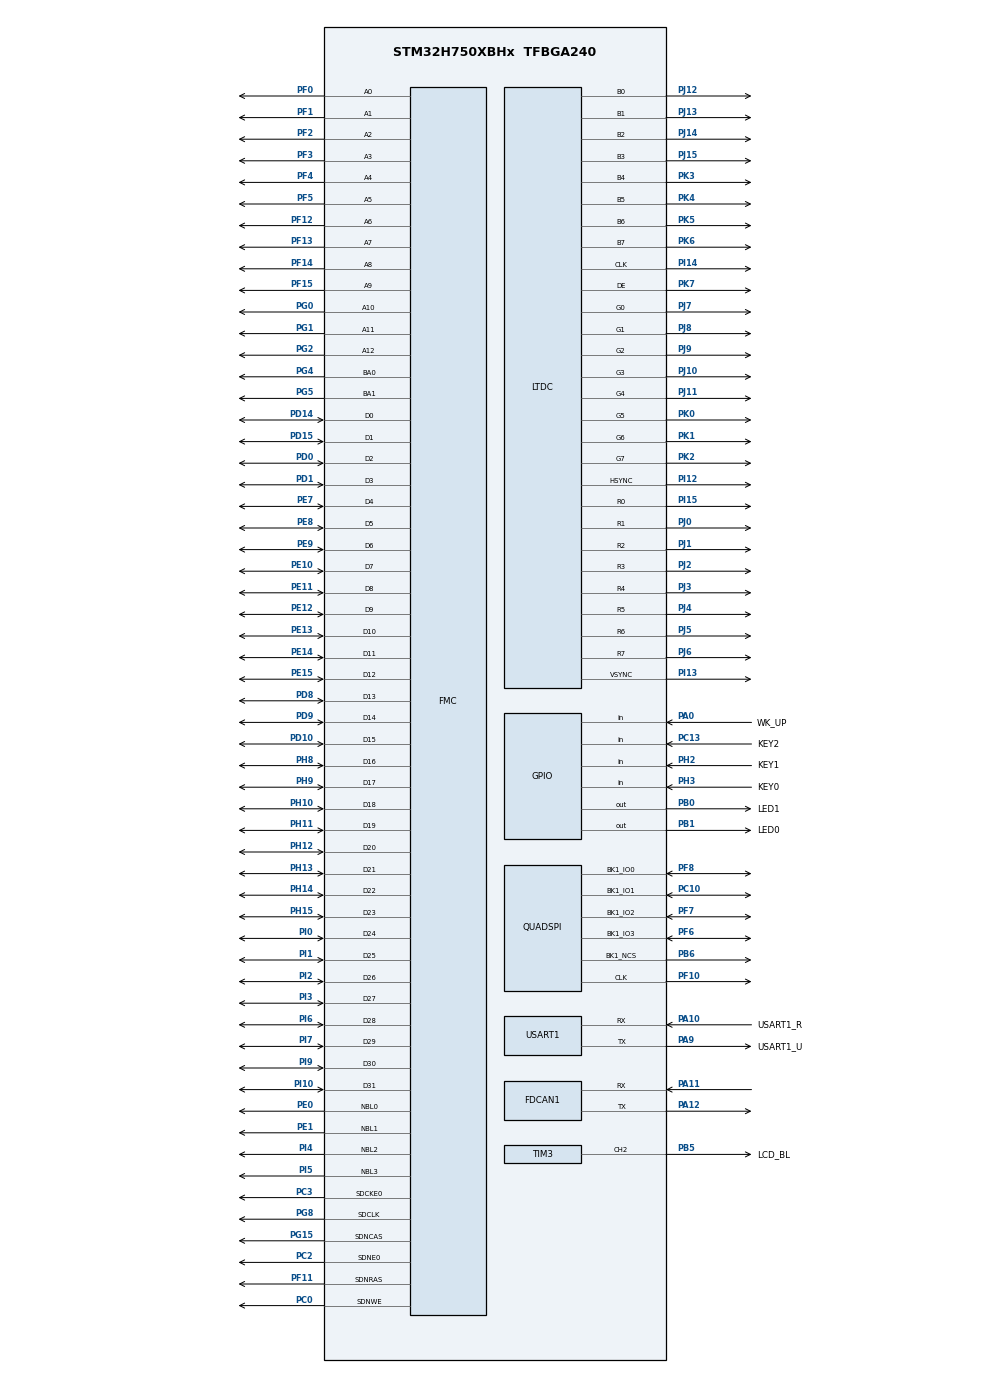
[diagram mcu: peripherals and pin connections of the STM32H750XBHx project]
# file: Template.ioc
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CORTEX_M7.CPU_DCache=Enabled
CORTEX_M7.CPU_ICache=Enabled
CORTEX_M7.default_mode_Activation=1
DMA2D.ColorMode=DMA2D_OUTPUT_RGB565
DMA2D.Mode=DMA2D_M2M
Dma.Request0=USART1_RX
Dma.USART1_RX.0.Direction=DMA_PERIPH_TO_MEMORY
Dma.USART1_RX.0.EventEnable=DISABLE
Dma.USART1_RX.0.FIFOMode=DMA_FIFOMODE_DISABLE
Dma.USART1_RX.0.Instance=DMA1_Stream0
Dma.USART1_RX.0.MemDataAlignment=DMA_MDATAALIGN_BYTE
Dma.USART1_RX.0.MemInc=DMA_MINC_ENABLE
Dma.USART1_RX.0.Mode=DMA_NORMAL
Dma.USART1_RX.0.PeriphDataAlignment=DMA_PDATAALIGN_BYTE
Dma.USART1_RX.0.PeriphInc=DMA_PINC_DISABLE
Dma.USART1_RX.0.Polarity=HAL_DMAMUX_REQ_GEN_RISING
Dma.USART1_RX.0.Priority=DMA_PRIORITY_LOW
Dma.USART1_RX.0.RequestNumber=1
Dma.USART1_RX.0.SignalID=NONE
Dma.USART1_RX.0.SyncEnable=DISABLE
Dma.USART1_RX.0.SyncPolarity=HAL_DMAMUX_SYNC_NO_EVENT
Dma.USART1_RX.0.SyncRequestNumber=1
Dma.USART1_RX.0.SyncSignalID=NONE
FDCAN1.AutoRetransmission=ENABLE
FDCAN1.CalculateBaudRateNominal=500000
FDCAN1.CalculateTimeBitNominal=2000
FDCAN1.CalculateTimeQuantumNominal=40.0
FDCAN1.DataPrescaler=1
FDCAN1.DataSyncJumpWidth=16
FDCAN1.DataTimeSeg1=31
FDCAN1.DataTimeSeg2=3
FDCAN1.ExtFiltersNbr=16
FDCAN1.NominalPrescaler=1
FDCAN1.NominalTimeSeg1=31
FDCAN1.NominalTimeSeg2=18
FDCAN1.RxBuffersNbr=8
FDCAN1.RxFifo0ElmtsNbr=32
FDCAN1.RxFifo1ElmtsNbr=32
FDCAN1.StdFiltersNbr=62
FDCAN1.TxFifoQueueElmtsNbr=32
FMC.CASLatency1=FMC_SDRAM_CAS_LATENCY_2
FMC.ColumnBitsNumber1=FMC_SDRAM_COLUMN_BITS_NUM_9
FMC.ExitSelfRefreshDelay1=8
FMC.LoadToActiveDelay1=2
FMC.RCDDelay1=2
FMC.RPDelay1=2
FMC.ReadBurst1=FMC_SDRAM_RBURST_ENABLE
FMC.ReadPipeDelay1=FMC_SDRAM_RPIPE_DELAY_0
FMC.RowCycleDelay1=7
FMC.SDClockPeriod1=FMC_SDRAM_CLOCK_PERIOD_2
FMC.SelfRefreshTime1=7
FMC.WriteRecoveryTime1=5
FREERTOS.HEAP_NUMBER=4
FREERTOS.Tasks01=GUITask,24,1024,GUI_Task,As weak,NULL,Dynamic,NULL,NULL
FREERTOS.configCHECK_FOR_STACK_OVERFLOW=2
FREERTOS.configENABLE_FPU=1
FREERTOS.configGENERATE_RUN_TIME_STATS=1
FREERTOS.configTIMER_TASK_STACK_DEPTH=512
FREERTOS.configTOTAL_HEAP_SIZE=0x20000
FREERTOS.configUSE_MALLOC_FAILED_HOOK=1
FREERTOS.configUSE_STATS_FORMATTING_FUNCTIONS=1
LTDC.ActiveW=800
LTDC.Alpha_L0=255
LTDC.Alpha_L1=255
LTDC.Blue_L0=0
LTDC.FBStartAdress_L0=0xC0000000
LTDC.HBP=88
LTDC.HFP=40
LTDC.HSync=48
LTDC.ImageHeight_L0=480
LTDC.ImageWidth_L0=800
LTDC.Layers=0
LTDC.PixelFormat_L0=LTDC_PIXEL_FORMAT_RGB565
LTDC.VBP=32
LTDC.VSync=3
LTDC.WindowX0_L1=200
LTDC.WindowX1_L0=800
LTDC.WindowX1_L1=600
LTDC.WindowY0_L1=200
LTDC.WindowY1_L0=480
LTDC.WindowY1_L1=600
Mcu.Family=STM32H7
Mcu.Name=STM32H750XBHx
Mcu.Package=TFBGA240
NVIC.DMA1_Stream0_IRQn=true\:5\:0\:true\:false\:true\:true\:false\:true\:true
NVIC.DMA2D_IRQn=true\:5\:0\:true\:false\:true\:true\:true\:true\:true
NVIC.FDCAN1_IT0_IRQn=true\:5\:0\:true\:false\:true\:true\:true\:true\:true
NVIC.FDCAN1_IT1_IRQn=true\:5\:0\:true\:false\:true\:true\:true\:true\:true
NVIC.FDCAN_CAL_IRQn=true\:5\:0\:true\:false\:true\:true\:true\:true\:true
NVIC.PriorityGroup=NVIC_PRIORITYGROUP_4
NVIC.TIM6_DAC_IRQn=true\:15\:0\:false\:false\:true\:false\:false\:true\:true
NVIC.TimeBase=TIM6_DAC_IRQn
NVIC.TimeBaseIP=TIM6
NVIC.USART1_IRQn=true\:5\:0\:true\:false\:true\:true\:true\:true\:true
PA0.GPIO_Label=WK_UP
PA0.GPIO_PuPd=GPIO_PULLDOWN
PA0.Signal=GPIO_Input
PA10.GPIO_Label=USART1_R
PA10.GPIO_PuPd=GPIO_PULLUP
PA10.Mode=Asynchronous
PA10.Signal=USART1_RX
PA11.GPIO_PuPd=GPIO_PULLUP
PA11.GPIO_Speed=GPIO_SPEED_FREQ_VERY_HIGH
PA11.Mode=FDCAN_Activate
PA11.Signal=FDCAN1_RX
PA12.GPIO_PuPd=GPIO_PULLUP
PA12.GPIO_Speed=GPIO_SPEED_FREQ_VERY_HIGH
PA12.Mode=FDCAN_Activate
PA12.Signal=FDCAN1_TX
PA13\ (JTMS/SWDIO).Mode=Serial_Wire
PA13\ (JTMS/SWDIO).Signal=DEBUG_JTMS-SWDIO
PA14\ (JTCK/SWCLK).Mode=Serial_Wire
PA14\ (JTCK/SWCLK).Signal=DEBUG_JTCK-SWCLK
PA9.GPIO_Label=USART1_U
PA9.Mode=Asynchronous
PA9.Signal=USART1_TX
PB0.GPIO_Label=LED1
PB0.GPIO_PuPd=GPIO_PULLUP
PB0.PinState=GPIO_PIN_SET
PB0.Signal=GPIO_Output
PB1.GPIO_Label=LED0
PB1.GPIO_PuPd=GPIO_PULLUP
PB1.PinState=GPIO_PIN_SET
PB1.Signal=GPIO_Output
PB5.GPIO_Label=LCD_BL
PB5.GPIO_ModeDefaultPP=GPIO_MODE_AF_PP
PB5.GPIO_PuPd=GPIO_NOPULL
PB5.Signal=S_TIM3_CH2
PB6.Mode=Single Bank 1
PB6.Signal=QUADSPI_BK1_NCS
PC0.GPIO_PuPd=GPIO_PULLUP
PC0.Signal=FMC_SDNWE
PC10.Mode=Single Bank 1
PC10.Signal=QUADSPI_BK1_IO1
PC13.GPIO_Label=KEY2
PC13.GPIO_PuPd=GPIO_PULLUP
PC13.Signal=GPIO_Input
PC2.GPIO_PuPd=GPIO_PULLUP
PC2.Mode=SdramChipSelect1_1
PC2.Signal=FMC_SDNE0
PC3.GPIO_PuPd=GPIO_PULLUP
PC3.Mode=SdramChipSelect1_1
PC3.Signal=FMC_SDCKE0
PD0.GPIO_PuPd=GPIO_PULLUP
PD0.Signal=FMC_D2_DA2
PD1.GPIO_PuPd=GPIO_PULLUP
PD1.Signal=FMC_D3_DA3
PD10.GPIO_PuPd=GPIO_PULLUP
PD10.Signal=FMC_D15_DA15
PD14.GPIO_PuPd=GPIO_PULLUP
PD14.Signal=FMC_D0_DA0
PD15.GPIO_PuPd=GPIO_PULLUP
PD15.Signal=FMC_D1_DA1
PD8.GPIO_PuPd=GPIO_PULLUP
PD8.Signal=FMC_D13_DA13
PD9.GPIO_PuPd=GPIO_PULLUP
PD9.Signal=FMC_D14_DA14
PE0.Signal=FMC_NBL0
PE1.Signal=FMC_NBL1
PE10.GPIO_PuPd=GPIO_PULLUP
PE10.Signal=FMC_D7_DA7
PE11.GPIO_PuPd=GPIO_PULLUP
PE11.Signal=FMC_D8_DA8
PE12.GPIO_PuPd=GPIO_PULLUP
PE12.Signal=FMC_D9_DA9
PE13.GPIO_PuPd=GPIO_PULLUP
PE13.Signal=FMC_D10_DA10
PE14.GPIO_PuPd=GPIO_PULLUP
PE14.Signal=FMC_D11_DA11
PE15.GPIO_PuPd=GPIO_PULLUP
PE15.Signal=FMC_D12_DA12
PE7.GPIO_PuPd=GPIO_PULLUP
PE7.Signal=FMC_D4_DA4
PE8.GPIO_PuPd=GPIO_PULLUP
PE8.Signal=FMC_D5_DA5
PE9.GPIO_PuPd=GPIO_PULLUP
PE9.Signal=FMC_D6_DA6
PF0.GPIO_PuPd=GPIO_PULLUP
PF0.Signal=FMC_A0
PF1.GPIO_PuPd=GPIO_PULLUP
PF1.Signal=FMC_A1
PF10.Mode=Single Bank 1
PF10.Signal=QUADSPI_CLK
PF11.GPIO_PuPd=GPIO_PULLUP
PF11.Signal=FMC_SDNRAS
PF12.GPIO_PuPd=GPIO_PULLUP
PF12.Signal=FMC_A6
PF13.GPIO_PuPd=GPIO_PULLUP
PF13.Signal=FMC_A7
PF14.GPIO_PuPd=GPIO_PULLUP
PF14.Signal=FMC_A8
PF15.GPIO_PuPd=GPIO_PULLUP
PF15.Signal=FMC_A9
PF2.GPIO_PuPd=GPIO_PULLUP
PF2.Signal=FMC_A2
PF3.GPIO_PuPd=GPIO_PULLUP
PF3.Signal=FMC_A3
PF4.GPIO_PuPd=GPIO_PULLUP
PF4.Signal=FMC_A4
PF5.GPIO_PuPd=GPIO_PULLUP
PF5.Signal=FMC_A5
PF6.Mode=Single Bank 1
PF6.Signal=QUADSPI_BK1_IO3
PF7.Mode=Single Bank 1
PF7.Signal=QUADSPI_BK1_IO2
PF8.Mode=Single Bank 1
PF8.Signal=QUADSPI_BK1_IO0
PG0.GPIO_PuPd=GPIO_PULLUP
PG0.Signal=FMC_A10
PG1.GPIO_PuPd=GPIO_PULLUP
PG1.Signal=FMC_A11
PG15.GPIO_PuPd=GPIO_PULLUP
PG15.Signal=FMC_SDNCAS
PG2.GPIO_PuPd=GPIO_PULLUP
PG2.Signal=FMC_A12
PG4.GPIO_PuPd=GPIO_PULLUP
PG4.Signal=FMC_A14_BA0
PG5.GPIO_PuPd=GPIO_PULLUP
PG5.Signal=FMC_A15_BA1
PG8.GPIO_PuPd=GPIO_PULLUP
PG8.Signal=FMC_SDCLK
PH0-OSC_IN\ (PH0).Mode=HSE-External-Oscillator
PH0-OSC_IN\ (PH0).Signal=RCC_OSC_IN
PH1-OSC_OUT\ (PH1).Mode=HSE-External-Oscillator
PH1-OSC_OUT\ (PH1).Signal=RCC_OSC_OUT
PH10.Signal=FMC_D18
PH11.Signal=FMC_D19
PH12.Signal=FMC_D20
PH13.Signal=FMC_D21
PH14.Signal=FMC_D22
PH15.Signal=FMC_D23
PH2.GPIO_Label=KEY1
PH2.GPIO_PuPd=GPIO_PULLUP
PH2.Signal=GPIO_Input
PH3.GPIO_Label=KEY0
PH3.GPIO_PuPd=GPIO_PULLUP
PH3.Signal=GPIO_Input
PH8.Signal=FMC_D16
PH9.Signal=FMC_D17
PI0.Signal=FMC_D24
PI1.Signal=FMC_D25
PI10.Signal=FMC_D31
PI12.GPIO_Speed=GPIO_SPEED_FREQ_VERY_HIGH
PI12.Mode=RGB888
PI12.Signal=LTDC_HSYNC
PI13.GPIO_Speed=GPIO_SPEED_FREQ_VERY_HIGH
PI13.Mode=RGB888
PI13.Signal=LTDC_VSYNC
PI14.GPIO_Speed=GPIO_SPEED_FREQ_VERY_HIGH
PI14.Mode=RGB888
PI14.Signal=LTDC_CLK
PI15.GPIO_Speed=GPIO_SPEED_FREQ_VERY_HIGH
PI15.Mode=RGB888
PI15.Signal=LTDC_R0
PI2.Signal=FMC_D26
PI3.Signal=FMC_D27
PI4.Signal=FMC_NBL2
PI5.Signal=FMC_NBL3
PI6.Signal=FMC_D28
PI7.Signal=FMC_D29
PI9.Signal=FMC_D30
PJ0.GPIO_Speed=GPIO_SPEED_FREQ_VERY_HIGH
PJ0.Mode=RGB888
PJ0.Signal=LTDC_R1
PJ1.GPIO_Speed=GPIO_SPEED_FREQ_VERY_HIGH
PJ1.Mode=RGB888
PJ1.Signal=LTDC_R2
PJ10.GPIO_Speed=GPIO_SPEED_FREQ_VERY_HIGH
PJ10.Mode=RGB888
PJ10.Signal=LTDC_G3
PJ11.GPIO_Speed=GPIO_SPEED_FREQ_VERY_HIGH
PJ11.Mode=RGB888
PJ11.Signal=LTDC_G4
PJ12.GPIO_Speed=GPIO_SPEED_FREQ_VERY_HIGH
PJ12.Mode=RGB888
PJ12.Signal=LTDC_B0
PJ13.GPIO_Speed=GPIO_SPEED_FREQ_VERY_HIGH
PJ13.Mode=RGB888
PJ13.Signal=LTDC_B1
PJ14.GPIO_Speed=GPIO_SPEED_FREQ_VERY_HIGH
PJ14.Mode=RGB888
PJ14.Signal=LTDC_B2
PJ15.GPIO_Speed=GPIO_SPEED_FREQ_VERY_HIGH
PJ15.Mode=RGB888
PJ15.Signal=LTDC_B3
PJ2.GPIO_Speed=GPIO_SPEED_FREQ_VERY_HIGH
PJ2.Mode=RGB888
PJ2.Signal=LTDC_R3
PJ3.GPIO_Speed=GPIO_SPEED_FREQ_VERY_HIGH
PJ3.Mode=RGB888
PJ3.Signal=LTDC_R4
PJ4.GPIO_Speed=GPIO_SPEED_FREQ_VERY_HIGH
PJ4.Mode=RGB888
PJ4.Signal=LTDC_R5
PJ5.GPIO_Speed=GPIO_SPEED_FREQ_VERY_HIGH
PJ5.Mode=RGB888
PJ5.Signal=LTDC_R6
PJ6.GPIO_Speed=GPIO_SPEED_FREQ_VERY_HIGH
PJ6.Mode=RGB888
PJ6.Signal=LTDC_R7
PJ7.GPIO_Speed=GPIO_SPEED_FREQ_VERY_HIGH
PJ7.Mode=RGB888
PJ7.Signal=LTDC_G0
PJ8.GPIO_Speed=GPIO_SPEED_FREQ_VERY_HIGH
PJ8.Mode=RGB888
PJ8.Signal=LTDC_G1
PJ9.GPIO_Speed=GPIO_SPEED_FREQ_VERY_HIGH
PJ9.Mode=RGB888
PJ9.Signal=LTDC_G2
PK0.GPIO_Speed=GPIO_SPEED_FREQ_VERY_HIGH
PK0.Mode=RGB888
PK0.Signal=LTDC_G5
PK1.GPIO_Speed=GPIO_SPEED_FREQ_VERY_HIGH
PK1.Mode=RGB888
PK1.Signal=LTDC_G6
PK2.GPIO_Speed=GPIO_SPEED_FREQ_VERY_HIGH
PK2.Mode=RGB888
PK2.Signal=LTDC_G7
PK3.GPIO_Speed=GPIO_SPEED_FREQ_VERY_HIGH
PK3.Mode=RGB888
PK3.Signal=LTDC_B4
PK4.GPIO_Speed=GPIO_SPEED_FREQ_VERY_HIGH
PK4.Mode=RGB888
PK4.Signal=LTDC_B5
PK5.GPIO_Speed=GPIO_SPEED_FREQ_VERY_HIGH
PK5.Mode=RGB888
PK5.Signal=LTDC_B6
PK6.GPIO_Speed=GPIO_SPEED_FREQ_VERY_HIGH
PK6.Mode=RGB888
PK6.Signal=LTDC_B7
PK7.GPIO_Speed=GPIO_SPEED_FREQ_VERY_HIGH
PK7.Mode=RGB888
PK7.Signal=LTDC_DE
ProjectManager.HeapSize=0x200
ProjectManager.StackSize=0x400
ProjectManager.TargetToolchain=MDK-ARM V5.32
QUADSPI.ChipSelectHighTime=QSPI_CS_HIGH_TIME_2_CYCLE
QUADSPI.ClockPrescaler=1
QUADSPI.FifoThreshold=32
QUADSPI.SampleShifting=QSPI_SAMPLE_SHIFTING_HALFCYCLE
RCC.ADCFreq_Value=50390625
RCC.APB1Freq_Value=120000000
RCC.APB2Freq_Value=120000000
RCC.APB3Freq_Value=120000000
RCC.APB4Freq_Value=120000000
RCC.CortexFreq_Value=480000000
RCC.D1PPRE=RCC_APB3_DIV2
RCC.D2PPRE1=RCC_APB1_DIV2
RCC.D2PPRE2=RCC_APB2_DIV2
RCC.D3PPRE=RCC_APB4_DIV2
RCC.DIVM1=5
RCC.DIVM3=5
RCC.DIVN1=192
RCC.DIVN3=120
RCC.DIVQ1=8
RCC.DIVR3=20
RCC.FDCANCLockSelection=RCC_FDCANCLKSOURCE_HSE
RCC.HCLKFreq_Value=240000000
RCC.HPRE=RCC_HCLK_DIV2
RCC.PLL3FRACN=0
RCC.PLLFRACN=0
RCC.PLLSourceVirtual=RCC_PLLSOURCE_HSE
RCC.SYSCLKFreq_VALUE=480000000
RCC.SYSCLKSource=RCC_SYSCLKSOURCE_PLLCLK
RCC.USBFreq_Value=120000000
SH.FMC_A0.0=FMC_A0,13b-sda1
SH.FMC_A1.0=FMC_A1,13b-sda1
SH.FMC_A10.0=FMC_A10,13b-sda1
SH.FMC_A11.0=FMC_A11,13b-sda1
SH.FMC_A12.0=FMC_A12,13b-sda1
SH.FMC_A14_BA0.0=FMC_BA0,FourSdramBanks1
SH.FMC_A15_BA1.0=FMC_BA1,FourSdramBanks1
SH.FMC_A2.0=FMC_A2,13b-sda1
SH.FMC_A3.0=FMC_A3,13b-sda1
SH.FMC_A4.0=FMC_A4,13b-sda1
SH.FMC_A5.0=FMC_A5,13b-sda1
SH.FMC_A6.0=FMC_A6,13b-sda1
SH.FMC_A7.0=FMC_A7,13b-sda1
SH.FMC_A8.0=FMC_A8,13b-sda1
SH.FMC_A9.0=FMC_A9,13b-sda1
SH.FMC_D0_DA0.0=FMC_D0,sd-32b-d1
SH.FMC_D10_DA10.0=FMC_D10,sd-32b-d1
SH.FMC_D11_DA11.0=FMC_D11,sd-32b-d1
SH.FMC_D12_DA12.0=FMC_D12,sd-32b-d1
SH.FMC_D13_DA13.0=FMC_D13,sd-32b-d1
SH.FMC_D14_DA14.0=FMC_D14,sd-32b-d1
SH.FMC_D15_DA15.0=FMC_D15,sd-32b-d1
SH.FMC_D16.0=FMC_D16,sd-32b-d1
SH.FMC_D17.0=FMC_D17,sd-32b-d1
SH.FMC_D18.0=FMC_D18,sd-32b-d1
SH.FMC_D19.0=FMC_D19,sd-32b-d1
SH.FMC_D1_DA1.0=FMC_D1,sd-32b-d1
SH.FMC_D20.0=FMC_D20,sd-32b-d1
SH.FMC_D21.0=FMC_D21,sd-32b-d1
SH.FMC_D22.0=FMC_D22,sd-32b-d1
SH.FMC_D23.0=FMC_D23,sd-32b-d1
SH.FMC_D24.0=FMC_D24,sd-32b-d1
SH.FMC_D25.0=FMC_D25,sd-32b-d1
SH.FMC_D26.0=FMC_D26,sd-32b-d1
SH.FMC_D27.0=FMC_D27,sd-32b-d1
SH.FMC_D28.0=FMC_D28,sd-32b-d1
SH.FMC_D29.0=FMC_D29,sd-32b-d1
SH.FMC_D2_DA2.0=FMC_D2,sd-32b-d1
SH.FMC_D30.0=FMC_D30,sd-32b-d1
SH.FMC_D31.0=FMC_D31,sd-32b-d1
SH.FMC_D3_DA3.0=FMC_D3,sd-32b-d1
SH.FMC_D4_DA4.0=FMC_D4,sd-32b-d1
SH.FMC_D5_DA5.0=FMC_D5,sd-32b-d1
SH.FMC_D6_DA6.0=FMC_D6,sd-32b-d1
SH.FMC_D7_DA7.0=FMC_D7,sd-32b-d1
SH.FMC_D8_DA8.0=FMC_D8,sd-32b-d1
SH.FMC_D9_DA9.0=FMC_D9,sd-32b-d1
SH.FMC_NBL0.0=FMC_NBL0,Sd4ByteEnable1
SH.FMC_NBL1.0=FMC_NBL1,Sd4ByteEnable1
SH.FMC_NBL2.0=FMC_NBL2,Sd4ByteEnable1
SH.FMC_NBL3.0=FMC_NBL3,Sd4ByteEnable1
SH.FMC_SDCLK.0=FMC_SDCLK,13b-sda1
SH.FMC_SDNCAS.0=FMC_SDNCAS,13b-sda1
SH.FMC_SDNRAS.0=FMC_SDNRAS,13b-sda1
SH.FMC_SDNWE.0=FMC_SDNWE,13b-sda1
SH.S_TIM3_CH2.0=TIM3_CH2,PWM Generation2 CH2
TIM2.Period=1000000000-1
TIM2.Prescaler=240-1
TIM3.AutoReloadPreload=TIM_AUTORELOAD_PRELOAD_ENABLE
TIM3.Channel-PWM\ Generation2\ CH2=TIM_CHANNEL_2
TIM3.Period=200-1
TIM3.Prescaler=24000-1
USART1.VirtualMode-Asynchronous=VM_ASYNC
VP_DMA2D_VS_DMA2D.Mode=DMA2D_Activate
VP_FREERTOS_VS_CMSIS_V2.Mode=CMSIS_V2
VP_MEMORYMAP_VS_MEMORYMAP.Mode=CurAppReg
VP_SYS_VS_tim6.Mode=TIM6
VP_TIM2_VS_ClockSourceINT.Mode=Internal
board=custom

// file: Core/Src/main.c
/* USER CODE BEGIN Header */
/**
  ******************************************************************************
  * @file           : main.c
  * @brief          : Main program body
  ******************************************************************************
  * @attention
  *
  * Copyright (c) 2026 STMicroelectronics.
  * All rights reserved.
  *
  * This software is licensed under terms that can be found in the LICENSE file
  * in the root directory of this software component.
  * If no LICENSE file comes with this software, it is provided AS-IS.
  *
  ******************************************************************************
  */
/* USER CODE END Header */
#include "main.h"
#include "cmsis_os.h"
#include "dma.h"
#include "dma2d.h"
#include "fdcan.h"
#include "ltdc.h"
#include "quadspi.h"
#include "tim.h"
#include "usart.h"
#include "gpio.h"
#include "fmc.h"

void SystemClock_Config(void);
static void MPU_Config(void);
void MX_FREERTOS_Init(void);
/* USER CODE BEGIN PFP */
typedef struct {
    uint32_t size;
    uint32_t sum;
    char fileName[128];
} FirmwareInfo_Def;

const FirmwareInfo_Def *firmwareInfo = 0;
/* USER CODE END PFP */

/* USER CODE BEGIN 0 */
// 定义一个 100x100 的实验方块缓冲区 (放到内外部 RAM 均可)
uint16_t test_buffer[100 * 200];
/* USER CODE END 0 */

int main(void)
{

  /* USER CODE BEGIN 1 */
   __disable_irq();
   SCB->VTOR = 0x90002000;
    SCB_DisableDCache();
    SCB_DisableICache();
    SCB_InvalidateICache();
    SCB_InvalidateDCache();
    __enable_irq();
    firmwareInfo = (FirmwareInfo_Def *)(0x90000000 + 0x400000ul);
    mpu_memory_protection(); /* 保护相关存储区域 */
  /* USER CODE END 1 */

  /* MPU Configuration--------------------------------------------------------*/
 // MPU_Config();

  /* Enable the CPU Cache */

  /* Enable I-Cache---------------------------------------------------------*/
  SCB_EnableICache();

  /* Enable D-Cache---------------------------------------------------------*/
  SCB_EnableDCache();

  /* MCU Configuration--------------------------------------------------------*/

  /* Reset of all peripherals, Initializes the Flash interface and the Systick. */
  HAL_Init();

  /* Configure the system clock */
  SystemClock_Config();

  /* Initialize all configured peripherals */
  MX_GPIO_Init();
  MX_DMA_Init();
  MX_USART1_UART_Init();
  //MX_QUADSPI_Init();
  MX_FDCAN1_Init();
  MX_FMC_Init();
  MX_TIM2_Init();
  MX_LTDC_Init();
  MX_TIM3_Init();
  MX_DMA2D_Init();
  /* USER CODE BEGIN 2 */
   led_init();
    LED0(0);
   printf("test start \r\n");

   //printf SCPI-message
   //   printf("test start  -->CAN\r\n");
//   SCPI_Config_Init();

//    FDCAN_FilterTypeDef sFilterConfig;
//    sFilterConfig.IdType = FDCAN_STANDARD_ID;
//    sFilterConfig.FilterIndex = 0;
//    sFilterConfig.FilterType = FDCAN_FILTER_MASK;
//    sFilterConfig.FilterConfig = FDCAN_FILTER_TO_RXFIFO0;
//    sFilterConfig.FilterID1 = 0x000;
//    sFilterConfig.FilterID2 = 0x000;

//    HAL_FDCAN_ConfigFilter(&hfdcan1, &sFilterConfig);
//    HAL_FDCAN_ActivateNotification(&hfdcan1, FDCAN_IT_RX_FIFO0_NEW_MESSAGE, 0);
//

  /* USER CODE END 2 */

  /* Init scheduler */
  osKernelInitialize();  /* Call init function for freertos objects (in cmsis_os2.c) */
  MX_FREERTOS_Init();

  /* Start scheduler */
  osKernelStart();

  /* We should never get here as control is now taken by the scheduler */

  /* Infinite loop */
  while (1)
  {

    /* USER CODE BEGIN 3 */
      uint8_t key = key_scan(0);
        if (key == KEY0_PRES)
        {

        }
        if (key == KEY1_PRES)
        {

        }
        if (key == KEY2_PRES)
        {

        }
  }
  /* USER CODE END 3 */
}

void SystemClock_Config(void)
{
  RCC_OscInitTypeDef RCC_OscInitStruct = {0};
  RCC_ClkInitTypeDef RCC_ClkInitStruct = {0};

  /** Supply configuration update enable
  */
  HAL_PWREx_ConfigSupply(PWR_LDO_SUPPLY);

  /** Configure the main internal regulator output voltage
  */
  __HAL_PWR_VOLTAGESCALING_CONFIG(PWR_REGULATOR_VOLTAGE_SCALE0);

  while(!__HAL_PWR_GET_FLAG(PWR_FLAG_VOSRDY)) {}

  /** Initializes the RCC Oscillators according to the specified parameters
  * in the RCC_OscInitTypeDef structure.
  */
  RCC_OscInitStruct.OscillatorType = RCC_OSCILLATORTYPE_HSE;
  RCC_OscInitStruct.HSEState = RCC_HSE_ON;
  RCC_OscInitStruct.PLL.PLLState = RCC_PLL_ON;
  RCC_OscInitStruct.PLL.PLLSource = RCC_PLLSOURCE_HSE;
  RCC_OscInitStruct.PLL.PLLM = 5;
  RCC_OscInitStruct.PLL.PLLN = 192;
  RCC_OscInitStruct.PLL.PLLP = 2;
  RCC_OscInitStruct.PLL.PLLQ = 8;
  RCC_OscInitStruct.PLL.PLLR = 2;
  RCC_OscInitStruct.PLL.PLLRGE = RCC_PLL1VCIRANGE_2;
  RCC_OscInitStruct.PLL.PLLVCOSEL = RCC_PLL1VCOWIDE;
  RCC_OscInitStruct.PLL.PLLFRACN = 0;
  if (HAL_RCC_OscConfig(&RCC_OscInitStruct) != HAL_OK)
  {
    Error_Handler();
  }

  /** Initializes the CPU, AHB and APB buses clocks
  */
  RCC_ClkInitStruct.ClockType = RCC_CLOCKTYPE_HCLK|RCC_CLOCKTYPE_SYSCLK
                              |RCC_CLOCKTYPE_PCLK1|RCC_CLOCKTYPE_PCLK2
                              |RCC_CLOCKTYPE_D3PCLK1|RCC_CLOCKTYPE_D1PCLK1;
  RCC_ClkInitStruct.SYSCLKSource = RCC_SYSCLKSOURCE_PLLCLK;
  RCC_ClkInitStruct.SYSCLKDivider = RCC_SYSCLK_DIV1;
  RCC_ClkInitStruct.AHBCLKDivider = RCC_HCLK_DIV2;
  RCC_ClkInitStruct.APB3CLKDivider = RCC_APB3_DIV2;
  RCC_ClkInitStruct.APB1CLKDivider = RCC_APB1_DIV2;
  RCC_ClkInitStruct.APB2CLKDivider = RCC_APB2_DIV2;
  RCC_ClkInitStruct.APB4CLKDivider = RCC_APB4_DIV2;

  if (HAL_RCC_ClockConfig(&RCC_ClkInitStruct, FLASH_LATENCY_4) != HAL_OK)
  {
    Error_Handler();
  }
}

 /* MPU Configuration */

void MPU_Config(void)
{
  MPU_Region_InitTypeDef MPU_InitStruct = {0};

  /* Disables the MPU */
  HAL_MPU_Disable();

  /** Initializes and configures the Region and the memory to be protected
  */
  MPU_InitStruct.Enable = MPU_REGION_ENABLE;
  MPU_InitStruct.Number = MPU_REGION_NUMBER0;
  MPU_InitStruct.BaseAddress = 0x0;
  MPU_InitStruct.Size = MPU_REGION_SIZE_4GB;
  MPU_InitStruct.SubRegionDisable = 0x87;
  MPU_InitStruct.TypeExtField = MPU_TEX_LEVEL0;
  MPU_InitStruct.AccessPermission = MPU_REGION_NO_ACCESS;
  MPU_InitStruct.DisableExec = MPU_INSTRUCTION_ACCESS_DISABLE;
  MPU_InitStruct.IsShareable = MPU_ACCESS_SHAREABLE;
  MPU_InitStruct.IsCacheable = MPU_ACCESS_NOT_CACHEABLE;
  MPU_InitStruct.IsBufferable = MPU_ACCESS_NOT_BUFFERABLE;

  HAL_MPU_ConfigRegion(&MPU_InitStruct);
  /* Enables the MPU */
  HAL_MPU_Enable(MPU_PRIVILEGED_DEFAULT);

}

void HAL_TIM_PeriodElapsedCallback(TIM_HandleTypeDef *htim)
{
  if (htim->Instance == TIM6)
  {
    HAL_IncTick();
  }
}

void Error_Handler(void)
{
  __disable_irq();
  while (1)
  {
  }
}
